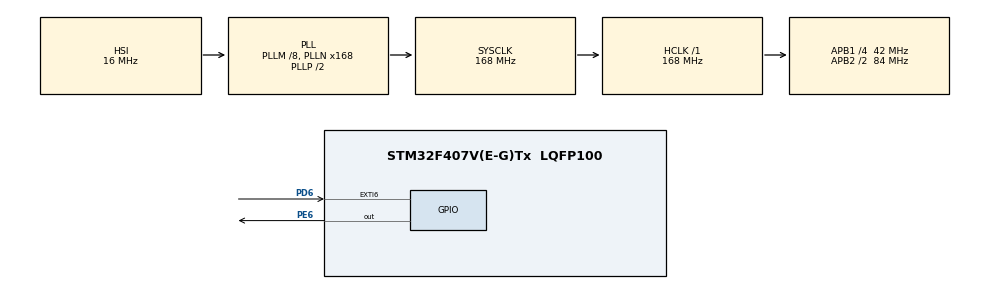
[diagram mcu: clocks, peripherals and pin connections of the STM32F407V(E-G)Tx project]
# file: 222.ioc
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Mcu.Family=STM32F4
Mcu.Name=STM32F407V(E-G)Tx
Mcu.Package=LQFP100
NVIC.EXTI9_5_IRQn=true\:0\:0\:false\:false\:true\:true\:true\:true
NVIC.PriorityGroup=NVIC_PRIORITYGROUP_4
NVIC.TIM7_IRQn=true\:0\:0\:false\:false\:true\:true\:true\:true
PA13.Mode=Serial_Wire
PA13.Signal=SYS_JTMS-SWDIO
PA14.Mode=Serial_Wire
PA14.Signal=SYS_JTCK-SWCLK
PC14-OSC32_IN.Mode=LSE-External-Oscillator
PC14-OSC32_IN.Signal=RCC_OSC32_IN
PC15-OSC32_OUT.Mode=LSE-External-Oscillator
PC15-OSC32_OUT.Signal=RCC_OSC32_OUT
PD6.GPIO_ModeDefaultEXTI=GPIO_MODE_IT_FALLING
PD6.GPIO_PuPd=GPIO_PULLUP
PD6.Signal=GPXTI6
PE6.GPIO_PuPd=GPIO_PULLUP
PE6.PinState=GPIO_PIN_SET
PE6.Signal=GPIO_Output
PH0-OSC_IN.Mode=HSE-External-Oscillator
PH0-OSC_IN.Signal=RCC_OSC_IN
PH1-OSC_OUT.Mode=HSE-External-Oscillator
PH1-OSC_OUT.Signal=RCC_OSC_OUT
ProjectManager.HeapSize=0x200
ProjectManager.StackSize=0x400
ProjectManager.TargetToolchain=Makefile
RCC.48MHZClocksFreq_Value=84000000
RCC.AHBFreq_Value=168000000
RCC.APB1CLKDivider=RCC_HCLK_DIV4
RCC.APB1Freq_Value=42000000
RCC.APB1TimFreq_Value=84000000
RCC.APB2CLKDivider=RCC_HCLK_DIV2
RCC.APB2Freq_Value=84000000
RCC.APB2TimFreq_Value=168000000
RCC.CortexFreq_Value=168000000
RCC.HCLKFreq_Value=168000000
RCC.HSE_VALUE=25000000
RCC.HSI_VALUE=16000000
RCC.PLLM=8
RCC.PLLN=168
RCC.SYSCLKFreq_VALUE=168000000
RCC.SYSCLKSource=RCC_SYSCLKSOURCE_PLLCLK
RCC.VCOOutputFreq_Value=336000000
TIM6.Period=65535-1
TIM6.Prescaler=84-1
TIM7.Period=104
TIM7.Prescaler=84-1
VP_TIM6_VS_ClockSourceINT.Mode=Enable_Timer
VP_TIM7_VS_ClockSourceINT.Mode=Enable_Timer
board=custom

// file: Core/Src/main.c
/* USER CODE BEGIN Header */
/**
  ******************************************************************************
  * @file           : main.c
  * @brief          : Main program body
  ******************************************************************************
  * @attention
  *
  * Copyright (c) 2023 STMicroelectronics.
  * All rights reserved.
  *
  * This software is licensed under terms that can be found in the LICENSE file
  * in the root directory of this software component.
  * If no LICENSE file comes with this software, it is provided AS-IS.
  *
  ******************************************************************************
  */
/* USER CODE END Header */
#include "main.h"
#include <stdio.h>
#include "uart.h"
#include "string.h"

/* USER CODE BEGIN Includes */
uint8_t len;
uint8_t buff[200];
/* USER CODE END Includes */

TIM_HandleTypeDef htim6;
TIM_HandleTypeDef htim7;

void SystemClock_Config(void);
static void MX_GPIO_Init(void);
static void MX_TIM6_Init(void);
static void MX_TIM7_Init(void);

int main(void)
{

  /* MCU Configuration--------------------------------------------------------*/

  /* Reset of all peripherals, Initializes the Flash interface and the Systick. */
  HAL_Init();

  /* Configure the system clock */
  SystemClock_Config();

  /* Initialize all configured peripherals */
  MX_GPIO_Init();
  MX_TIM6_Init();
  MX_TIM7_Init();

  /* Infinite loop */
  while (1)
  {
      if(S_Uart_Rx_Handler(buff,&len))
        {
            S_Uart_Send_Buff(buff,len);            //将收到的数据发送出去
            memset(buff,0x00,200);  //清除缓存
        }

     S_Uart_One_Tx('a');
    //  S_Uart_Send_Buff(p_Arr1,sizeof(p_Arr1) / sizeof(p_Arr1[0]));
    //  S_Uart_Send_Str(AT_CMD_softAP);
     HAL_Delay(100);
  }
}

void SystemClock_Config(void)
{
  RCC_OscInitTypeDef RCC_OscInitStruct = {0};
  RCC_ClkInitTypeDef RCC_ClkInitStruct = {0};

  /** Configure the main internal regulator output voltage
  */
  __HAL_RCC_PWR_CLK_ENABLE();
  __HAL_PWR_VOLTAGESCALING_CONFIG(PWR_REGULATOR_VOLTAGE_SCALE1);

  /** Initializes the RCC Oscillators according to the specified parameters
  * in the RCC_OscInitTypeDef structure.
  */
  RCC_OscInitStruct.OscillatorType = RCC_OSCILLATORTYPE_HSI;
  RCC_OscInitStruct.HSIState = RCC_HSI_ON;
  RCC_OscInitStruct.HSICalibrationValue = RCC_HSICALIBRATION_DEFAULT;
  RCC_OscInitStruct.PLL.PLLState = RCC_PLL_ON;
  RCC_OscInitStruct.PLL.PLLSource = RCC_PLLSOURCE_HSI;
  RCC_OscInitStruct.PLL.PLLM = 8;
  RCC_OscInitStruct.PLL.PLLN = 168;
  RCC_OscInitStruct.PLL.PLLP = RCC_PLLP_DIV2;
  RCC_OscInitStruct.PLL.PLLQ = 4;
  if (HAL_RCC_OscConfig(&RCC_OscInitStruct) != HAL_OK)
  {
    Error_Handler();
  }

  /** Initializes the CPU, AHB and APB buses clocks
  */
  RCC_ClkInitStruct.ClockType = RCC_CLOCKTYPE_HCLK|RCC_CLOCKTYPE_SYSCLK
                              |RCC_CLOCKTYPE_PCLK1|RCC_CLOCKTYPE_PCLK2;
  RCC_ClkInitStruct.SYSCLKSource = RCC_SYSCLKSOURCE_PLLCLK;
  RCC_ClkInitStruct.AHBCLKDivider = RCC_SYSCLK_DIV1;
  RCC_ClkInitStruct.APB1CLKDivider = RCC_HCLK_DIV4;
  RCC_ClkInitStruct.APB2CLKDivider = RCC_HCLK_DIV2;

  if (HAL_RCC_ClockConfig(&RCC_ClkInitStruct, FLASH_LATENCY_5) != HAL_OK)
  {
    Error_Handler();
  }
}

static void MX_TIM6_Init(void)
{

  TIM_MasterConfigTypeDef sMasterConfig = {0};

  htim6.Instance = TIM6;
  htim6.Init.Prescaler = 84-1;
  htim6.Init.CounterMode = TIM_COUNTERMODE_UP;
  htim6.Init.Period = 65535-1;
  htim6.Init.AutoReloadPreload = TIM_AUTORELOAD_PRELOAD_DISABLE;
  if (HAL_TIM_Base_Init(&htim6) != HAL_OK)
  {
    Error_Handler();
  }
  sMasterConfig.MasterOutputTrigger = TIM_TRGO_RESET;
  sMasterConfig.MasterSlaveMode = TIM_MASTERSLAVEMODE_DISABLE;
  if (HAL_TIMEx_MasterConfigSynchronization(&htim6, &sMasterConfig) != HAL_OK)
  {
    Error_Handler();
  }

}

static void MX_TIM7_Init(void)
{

  TIM_MasterConfigTypeDef sMasterConfig = {0};

  htim7.Instance = TIM7;
  htim7.Init.Prescaler = 84-1;
  htim7.Init.CounterMode = TIM_COUNTERMODE_UP;
  htim7.Init.Period = 104;
  htim7.Init.AutoReloadPreload = TIM_AUTORELOAD_PRELOAD_DISABLE;
  if (HAL_TIM_Base_Init(&htim7) != HAL_OK)
  {
    Error_Handler();
  }
  sMasterConfig.MasterOutputTrigger = TIM_TRGO_RESET;
  sMasterConfig.MasterSlaveMode = TIM_MASTERSLAVEMODE_DISABLE;
  if (HAL_TIMEx_MasterConfigSynchronization(&htim7, &sMasterConfig) != HAL_OK)
  {
    Error_Handler();
  }

}

static void MX_GPIO_Init(void)
{
  GPIO_InitTypeDef GPIO_InitStruct = {0};

  /* GPIO Ports Clock Enable */
  __HAL_RCC_GPIOE_CLK_ENABLE();
  __HAL_RCC_GPIOC_CLK_ENABLE();
  __HAL_RCC_GPIOH_CLK_ENABLE();
  __HAL_RCC_GPIOA_CLK_ENABLE();
  __HAL_RCC_GPIOD_CLK_ENABLE();

  /*Configure GPIO pin Output Level */
  HAL_GPIO_WritePin(GPIOE, GPIO_PIN_6, GPIO_PIN_SET);

  /*Configure GPIO pin : PE6 */
  GPIO_InitStruct.Pin = GPIO_PIN_6;
  GPIO_InitStruct.Mode = GPIO_MODE_OUTPUT_PP;
  GPIO_InitStruct.Pull = GPIO_PULLUP;
  GPIO_InitStruct.Speed = GPIO_SPEED_FREQ_LOW;
  HAL_GPIO_Init(GPIOE, &GPIO_InitStruct);

  /*Configure GPIO pin : PD6 */
  GPIO_InitStruct.Pin = GPIO_PIN_6;
  GPIO_InitStruct.Mode = GPIO_MODE_IT_FALLING;
  GPIO_InitStruct.Pull = GPIO_PULLUP;
  HAL_GPIO_Init(GPIOD, &GPIO_InitStruct);

  /* EXTI interrupt init*/
  HAL_NVIC_SetPriority(EXTI9_5_IRQn, 0, 0);
  HAL_NVIC_EnableIRQ(EXTI9_5_IRQn);

}

void Error_Handler(void)
{
  __disable_irq();
  while (1)
  {
  }
}
